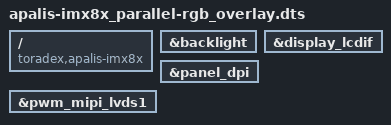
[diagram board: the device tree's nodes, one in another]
// SPDX-License-Identifier: GPL-2.0-or-later OR MIT
/*
 * Copyright 2020-2021 Toradex
 */

// Enable the parallel RGB interface on Apalis iMX8X

/dts-v1/;
/plugin/;

/ {
	compatible = "toradex,apalis-imx8x";
};

&backlight {
	status = "okay";
};

&display_lcdif {
	status = "okay";
};

&panel_dpi {
	status = "okay";
};

/* Apalis BKL1_PWM */
&pwm_mipi_lvds1 {
	status = "okay";
};
